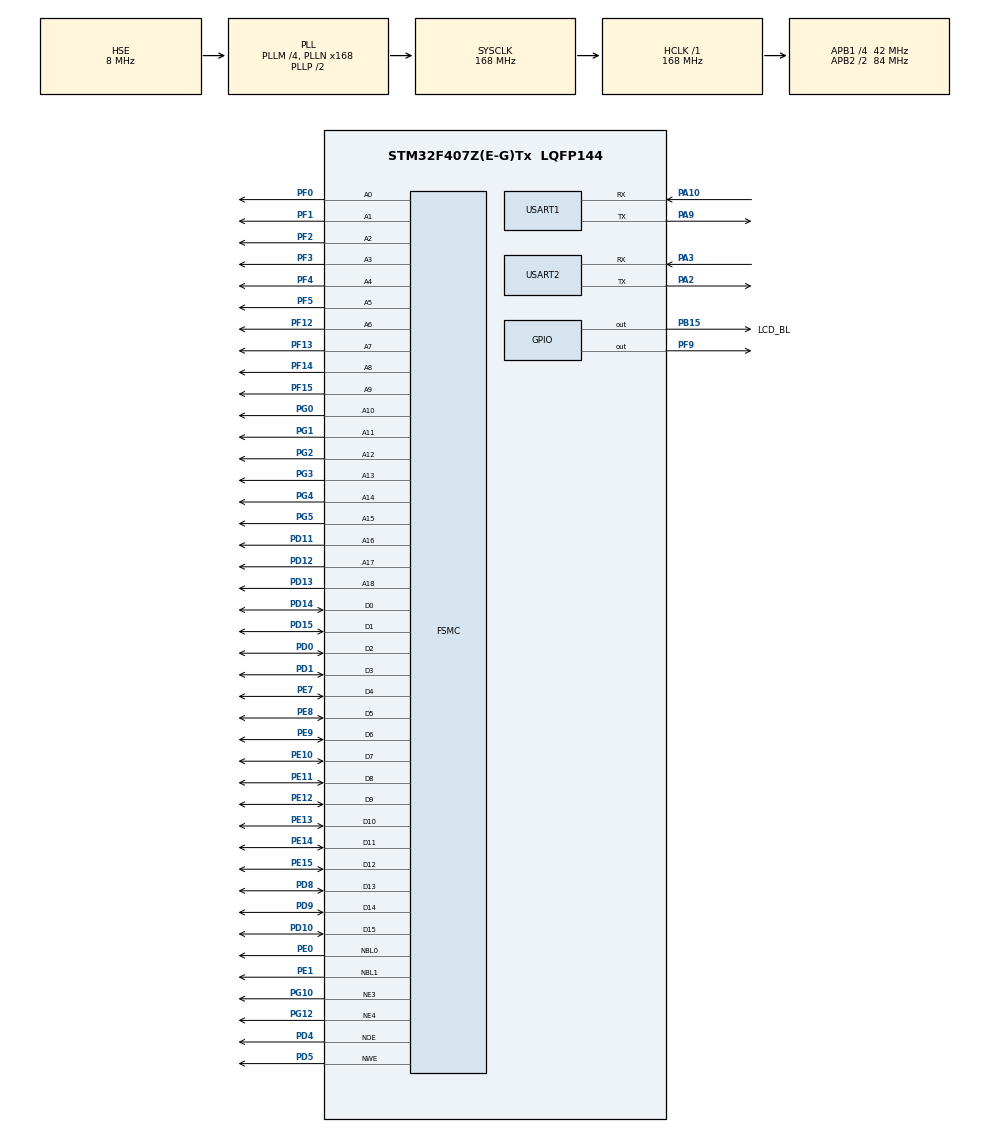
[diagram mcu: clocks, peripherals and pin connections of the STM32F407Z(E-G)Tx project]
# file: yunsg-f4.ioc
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Dma.Request0=USART2_RX
Dma.Request1=USART2_TX
Dma.USART2_RX.0.Direction=DMA_PERIPH_TO_MEMORY
Dma.USART2_RX.0.FIFOMode=DMA_FIFOMODE_DISABLE
Dma.USART2_RX.0.Instance=DMA1_Stream5
Dma.USART2_RX.0.MemDataAlignment=DMA_MDATAALIGN_BYTE
Dma.USART2_RX.0.MemInc=DMA_MINC_ENABLE
Dma.USART2_RX.0.Mode=DMA_NORMAL
Dma.USART2_RX.0.PeriphDataAlignment=DMA_PDATAALIGN_BYTE
Dma.USART2_RX.0.PeriphInc=DMA_PINC_DISABLE
Dma.USART2_RX.0.Priority=DMA_PRIORITY_LOW
Dma.USART2_TX.1.Direction=DMA_MEMORY_TO_PERIPH
Dma.USART2_TX.1.FIFOMode=DMA_FIFOMODE_DISABLE
Dma.USART2_TX.1.Instance=DMA1_Stream6
Dma.USART2_TX.1.MemDataAlignment=DMA_MDATAALIGN_BYTE
Dma.USART2_TX.1.MemInc=DMA_MINC_ENABLE
Dma.USART2_TX.1.Mode=DMA_NORMAL
Dma.USART2_TX.1.PeriphDataAlignment=DMA_PDATAALIGN_BYTE
Dma.USART2_TX.1.PeriphInc=DMA_PINC_DISABLE
Dma.USART2_TX.1.Priority=DMA_PRIORITY_LOW
FREERTOS.Tasks01=defaultTask,24,128,StartDefaultTask,Default,NULL,Dynamic,NULL,NULL
FSMC.AddressSetupTime1=0x0F
FSMC.AddressSetupTime2=2
FSMC.BusTurnAroundDuration1=0
FSMC.BusTurnAroundDuration2=0
FSMC.DataSetupTime1=60
FSMC.DataSetupTime2=8
FSMC.ExtendedAddressSetupTime1=9
FSMC.ExtendedBusTurnAroundDuration1=0
FSMC.ExtendedDataSetupTime1=9
FSMC.ExtendedMode1=FSMC_EXTENDED_MODE_ENABLE
FSMC.WriteOperation2=FSMC_WRITE_OPERATION_ENABLE
Mcu.Family=STM32F4
Mcu.Name=STM32F407Z(E-G)Tx
Mcu.Package=LQFP144
NVIC.DMA1_Stream5_IRQn=true\:5\:0\:false\:false\:true\:true\:false\:true\:true
NVIC.DMA1_Stream6_IRQn=true\:5\:0\:false\:false\:true\:true\:false\:true\:true
NVIC.PriorityGroup=NVIC_PRIORITYGROUP_4
NVIC.TIM1_UP_TIM10_IRQn=true\:15\:0\:false\:false\:true\:false\:false\:true\:true
NVIC.TimeBase=TIM1_UP_TIM10_IRQn
NVIC.TimeBaseIP=TIM1
NVIC.USART1_IRQn=true\:5\:0\:false\:false\:true\:true\:true\:true\:true
NVIC.USART2_IRQn=true\:5\:0\:false\:false\:true\:true\:true\:true\:true
PA10.Mode=Asynchronous
PA10.Signal=USART1_RX
PA13.Mode=Serial_Wire
PA13.Signal=SYS_JTMS-SWDIO
PA14.Mode=Serial_Wire
PA14.Signal=SYS_JTCK-SWCLK
PA2.Mode=Asynchronous
PA2.Signal=USART2_TX
PA3.Mode=Asynchronous
PA3.Signal=USART2_RX
PA9.Mode=Asynchronous
PA9.Signal=USART1_TX
PB15.GPIO_Label=LCD_BL
PB15.Signal=GPIO_Output
PD0.Signal=FSMC_D2_DA2
PD1.Signal=FSMC_D3_DA3
PD10.Signal=FSMC_D15_DA15
PD11.Signal=FSMC_A16_CLE
PD12.Signal=FSMC_A17_ALE
PD13.Signal=FSMC_A18
PD14.Signal=FSMC_D0_DA0
PD15.Signal=FSMC_D1_DA1
PD4.Signal=FSMC_NOE
PD5.Signal=FSMC_NWE
PD8.Signal=FSMC_D13_DA13
PD9.Signal=FSMC_D14_DA14
PE0.Signal=FSMC_NBL0
PE1.Signal=FSMC_NBL1
PE10.Signal=FSMC_D7_DA7
PE11.Signal=FSMC_D8_DA8
PE12.Signal=FSMC_D9_DA9
PE13.Signal=FSMC_D10_DA10
PE14.Signal=FSMC_D11_DA11
PE15.Signal=FSMC_D12_DA12
PE7.Signal=FSMC_D4_DA4
PE8.Signal=FSMC_D5_DA5
PE9.Signal=FSMC_D6_DA6
PF0.Signal=FSMC_A0
PF1.Signal=FSMC_A1
PF12.Signal=FSMC_A6
PF13.Signal=FSMC_A7
PF14.Signal=FSMC_A8
PF15.Signal=FSMC_A9
PF2.Signal=FSMC_A2
PF3.Signal=FSMC_A3
PF4.Signal=FSMC_A4
PF5.Signal=FSMC_A5
PF9.Signal=GPIO_Output
PG0.Signal=FSMC_A10
PG1.Signal=FSMC_A11
PG10.Mode=NorPsramChipSelect3_2
PG10.Signal=FSMC_NE3
PG12.Mode=NorPsramChipSelect4_1
PG12.Signal=FSMC_NE4
PG2.Signal=FSMC_A12
PG3.Signal=FSMC_A13
PG4.Signal=FSMC_A14
PG5.Signal=FSMC_A15
PH0-OSC_IN.Mode=HSE-External-Oscillator
PH0-OSC_IN.Signal=RCC_OSC_IN
PH1-OSC_OUT.Mode=HSE-External-Oscillator
PH1-OSC_OUT.Signal=RCC_OSC_OUT
ProjectManager.HeapSize=0x200
ProjectManager.StackSize=0x800
ProjectManager.TargetToolchain=Makefile
RCC.48MHZClocksFreq_Value=84000000
RCC.AHBFreq_Value=168000000
RCC.APB1CLKDivider=RCC_HCLK_DIV4
RCC.APB1Freq_Value=42000000
RCC.APB1TimFreq_Value=84000000
RCC.APB2CLKDivider=RCC_HCLK_DIV2
RCC.APB2Freq_Value=84000000
RCC.APB2TimFreq_Value=168000000
RCC.CortexFreq_Value=168000000
RCC.HCLKFreq_Value=168000000
RCC.HSE_VALUE=8000000
RCC.HSI_VALUE=16000000
RCC.LSE_VALUE=32768
RCC.PLLM=4
RCC.PLLN=168
RCC.PLLSourceVirtual=RCC_PLLSOURCE_HSE
RCC.SYSCLKFreq_VALUE=168000000
RCC.SYSCLKSource=RCC_SYSCLKSOURCE_PLLCLK
RCC.VCOOutputFreq_Value=336000000
SH.FSMC_A0.0=FSMC_A0,19b-a2
SH.FSMC_A1.0=FSMC_A1,19b-a2
SH.FSMC_A10.0=FSMC_A10,19b-a2
SH.FSMC_A11.0=FSMC_A11,19b-a2
SH.FSMC_A12.0=FSMC_A12,19b-a2
SH.FSMC_A13.0=FSMC_A13,19b-a2
SH.FSMC_A14.0=FSMC_A14,19b-a2
SH.FSMC_A15.0=FSMC_A15,19b-a2
SH.FSMC_A16_CLE.0=FSMC_A16,19b-a2
SH.FSMC_A17_ALE.0=FSMC_A17,19b-a2
SH.FSMC_A18.0=FSMC_A18,19b-a2
SH.FSMC_A2.0=FSMC_A2,19b-a2
SH.FSMC_A3.0=FSMC_A3,19b-a2
SH.FSMC_A4.0=FSMC_A4,19b-a2
SH.FSMC_A5.0=FSMC_A5,19b-a2
SH.FSMC_A6.0=FSMC_A6,A6_1
SH.FSMC_A6.1=FSMC_A6,19b-a2
SH.FSMC_A7.0=FSMC_A7,19b-a2
SH.FSMC_A8.0=FSMC_A8,19b-a2
SH.FSMC_A9.0=FSMC_A9,19b-a2
SH.FSMC_D0_DA0.0=FSMC_D0,16b-d1
SH.FSMC_D0_DA0.1=FSMC_D0,16b-d2
SH.FSMC_D10_DA10.0=FSMC_D10,16b-d1
SH.FSMC_D10_DA10.1=FSMC_D10,16b-d2
SH.FSMC_D11_DA11.0=FSMC_D11,16b-d1
SH.FSMC_D11_DA11.1=FSMC_D11,16b-d2
SH.FSMC_D12_DA12.0=FSMC_D12,16b-d1
SH.FSMC_D12_DA12.1=FSMC_D12,16b-d2
SH.FSMC_D13_DA13.0=FSMC_D13,16b-d1
SH.FSMC_D13_DA13.1=FSMC_D13,16b-d2
SH.FSMC_D14_DA14.0=FSMC_D14,16b-d1
SH.FSMC_D14_DA14.1=FSMC_D14,16b-d2
SH.FSMC_D15_DA15.0=FSMC_D15,16b-d1
SH.FSMC_D15_DA15.1=FSMC_D15,16b-d2
SH.FSMC_D1_DA1.0=FSMC_D1,16b-d1
SH.FSMC_D1_DA1.1=FSMC_D1,16b-d2
SH.FSMC_D2_DA2.0=FSMC_D2,16b-d1
SH.FSMC_D2_DA2.1=FSMC_D2,16b-d2
SH.FSMC_D3_DA3.0=FSMC_D3,16b-d1
SH.FSMC_D3_DA3.1=FSMC_D3,16b-d2
SH.FSMC_D4_DA4.0=FSMC_D4,16b-d1
SH.FSMC_D4_DA4.1=FSMC_D4,16b-d2
SH.FSMC_D5_DA5.0=FSMC_D5,16b-d1
SH.FSMC_D5_DA5.1=FSMC_D5,16b-d2
SH.FSMC_D6_DA6.0=FSMC_D6,16b-d1
SH.FSMC_D6_DA6.1=FSMC_D6,16b-d2
SH.FSMC_D7_DA7.0=FSMC_D7,16b-d1
SH.FSMC_D7_DA7.1=FSMC_D7,16b-d2
SH.FSMC_D8_DA8.0=FSMC_D8,16b-d1
SH.FSMC_D8_DA8.1=FSMC_D8,16b-d2
SH.FSMC_D9_DA9.0=FSMC_D9,16b-d1
SH.FSMC_D9_DA9.1=FSMC_D9,16b-d2
SH.FSMC_NBL0.0=FSMC_NBL0,2ByteEnable2
SH.FSMC_NBL1.0=FSMC_NBL1,2ByteEnable2
SH.FSMC_NOE.0=FSMC_NOE,Lcd1
SH.FSMC_NOE.1=FSMC_NOE,Sram2
SH.FSMC_NWE.0=FSMC_NWE,Lcd1
SH.FSMC_NWE.1=FSMC_NWE,Sram2
USART1.VirtualMode=VM_ASYNC
USART2.VirtualMode=VM_ASYNC
VP_FREERTOS_VS_CMSIS_V2.Mode=CMSIS_V2
VP_SYS_VS_tim1.Mode=TIM1
board=custom

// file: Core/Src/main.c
/* USER CODE BEGIN Header */
/**
  ******************************************************************************
  * @file           : main.c
  * @brief          : Main program body
  ******************************************************************************
  * @attention
  *
  * Copyright (c) 2025 STMicroelectronics.
  * All rights reserved.
  *
  * This software is licensed under terms that can be found in the LICENSE file
  * in the root directory of this software component.
  * If no LICENSE file comes with this software, it is provided AS-IS.
  *
  ******************************************************************************
  */
/* USER CODE END Header */
#include "main.h"
#include "cmsis_os.h"
#include "dma.h"
#include "usart.h"
#include "gpio.h"
#include "fsmc.h"

void SystemClock_Config(void);
void MX_FREERTOS_Init(void);

int main(void)
{

  /* MCU Configuration--------------------------------------------------------*/

  /* Reset of all peripherals, Initializes the Flash interface and the Systick. */
  HAL_Init();

  /* Configure the system clock */
  SystemClock_Config();

  /* Initialize all configured peripherals */
  MX_GPIO_Init();
  MX_DMA_Init();
  MX_USART1_UART_Init();
  MX_USART2_UART_Init();
  MX_FSMC_Init();

  /* Init scheduler */
  osKernelInitialize();

  /* Call init function for freertos objects (in cmsis_os2.c) */
  MX_FREERTOS_Init();

  /* Start scheduler */
  osKernelStart();

  /* We should never get here as control is now taken by the scheduler */

  /* Infinite loop */
  while (1)
  {

  }
}

void SystemClock_Config(void)
{
  RCC_OscInitTypeDef RCC_OscInitStruct = {0};
  RCC_ClkInitTypeDef RCC_ClkInitStruct = {0};

  /** Configure the main internal regulator output voltage
  */
  __HAL_RCC_PWR_CLK_ENABLE();
  __HAL_PWR_VOLTAGESCALING_CONFIG(PWR_REGULATOR_VOLTAGE_SCALE1);

  /** Initializes the RCC Oscillators according to the specified parameters
  * in the RCC_OscInitTypeDef structure.
  */
  RCC_OscInitStruct.OscillatorType = RCC_OSCILLATORTYPE_HSE;
  RCC_OscInitStruct.HSEState = RCC_HSE_ON;
  RCC_OscInitStruct.PLL.PLLState = RCC_PLL_ON;
  RCC_OscInitStruct.PLL.PLLSource = RCC_PLLSOURCE_HSE;
  RCC_OscInitStruct.PLL.PLLM = 4;
  RCC_OscInitStruct.PLL.PLLN = 168;
  RCC_OscInitStruct.PLL.PLLP = RCC_PLLP_DIV2;
  RCC_OscInitStruct.PLL.PLLQ = 4;
  if (HAL_RCC_OscConfig(&RCC_OscInitStruct) != HAL_OK)
  {
    Error_Handler();
  }

  /** Initializes the CPU, AHB and APB buses clocks
  */
  RCC_ClkInitStruct.ClockType = RCC_CLOCKTYPE_HCLK|RCC_CLOCKTYPE_SYSCLK
                              |RCC_CLOCKTYPE_PCLK1|RCC_CLOCKTYPE_PCLK2;
  RCC_ClkInitStruct.SYSCLKSource = RCC_SYSCLKSOURCE_PLLCLK;
  RCC_ClkInitStruct.AHBCLKDivider = RCC_SYSCLK_DIV1;
  RCC_ClkInitStruct.APB1CLKDivider = RCC_HCLK_DIV4;
  RCC_ClkInitStruct.APB2CLKDivider = RCC_HCLK_DIV2;

  if (HAL_RCC_ClockConfig(&RCC_ClkInitStruct, FLASH_LATENCY_5) != HAL_OK)
  {
    Error_Handler();
  }
}

void HAL_TIM_PeriodElapsedCallback(TIM_HandleTypeDef *htim)
{
  if (htim->Instance == TIM1)
  {
    HAL_IncTick();
  }
}

void Error_Handler(void)
{
  __disable_irq();
  while (1)
  {
  }
}

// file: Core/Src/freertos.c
/* USER CODE BEGIN Header */
/**
 ******************************************************************************
 * File Name          : freertos.c
 * Description        : Code for freertos applications
 ******************************************************************************
 * @attention
 *
 * Copyright (c) 2025 STMicroelectronics.
 * All rights reserved.
 *
 * This software is licensed under terms that can be found in the LICENSE file
 * in the root directory of this software component.
 * If no LICENSE file comes with this software, it is provided AS-IS.
 *
 ******************************************************************************
 */
/* USER CODE END Header */

#include "FreeRTOS.h"
#include "task.h"
#include "main.h"
#include "cmsis_os.h"

/* USER CODE BEGIN Includes */
#include "user_TaskInit.h"
#include "stdio.h"
#include "user_TaskInit.h"
/* USER CODE END Includes */

/* USER CODE BEGIN Variables */

// wifi控制任务

/* USER CODE END Variables */
/* Definitions for defaultTask */
osThreadId_t defaultTaskHandle;
const osThreadAttr_t defaultTask_attributes = {
  .name = "defaultTask",
  .stack_size = 128 * 4,
  .priority = (osPriority_t) osPriorityNormal,
};

void StartDefaultTask(void *argument);

void MX_FREERTOS_Init(void); /* (MISRA C 2004 rule 8.1) */

void MX_FREERTOS_Init(void) {
  /* USER CODE BEGIN Init */
  User_Tasks_Init();
  /* USER CODE END Init */

  /* Create the thread(s) */
  /* creation of defaultTask */
  defaultTaskHandle = osThreadNew(StartDefaultTask, NULL, &defaultTask_attributes);

}

void StartDefaultTask(void *argument)
{
  /* USER CODE BEGIN StartDefaultTask */
  /* Infinite loop */
  for (;;)
  {
    HAL_GPIO_TogglePin(GPIOF,GPIO_PIN_9);
    osDelay(500);
  }
  /* USER CODE END StartDefaultTask */
}
